# RL6845_IP_SVD register map
Vendor: Realtek
Registers are 32-bit, read-write, reset 0x0 unless marked. A register's access mark holds for its fields unless they carry their own. Offsets are from the block's base; [hi:lo] are bit positions; {n}, {i} and the like mark numbered series.

## LEDC_REG
Base 0x41105000
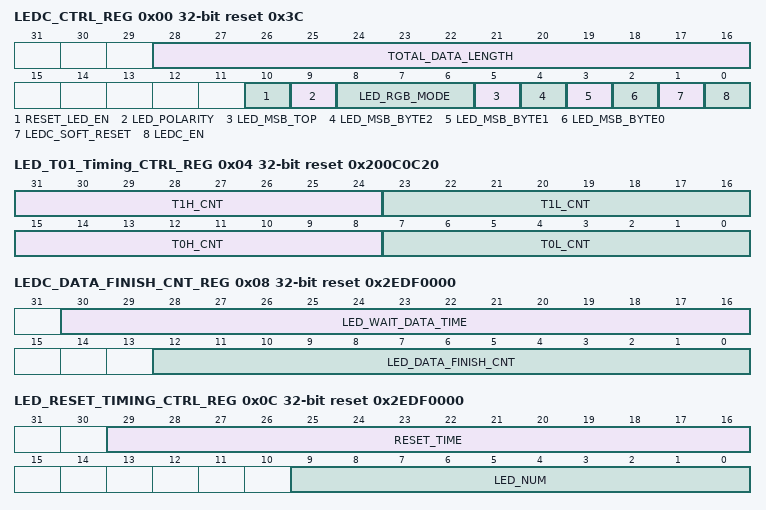
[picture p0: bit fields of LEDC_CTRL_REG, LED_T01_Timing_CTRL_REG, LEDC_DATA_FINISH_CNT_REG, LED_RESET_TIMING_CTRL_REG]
0x00 LEDC_CTRL_REG reset 0x3C — LEDC Control Register
  [28:16] TOTAL_DATA_LENGTH — Total length of transfer data, range from 1 to 8K (unit: 32 bits, only low 24-bit is valid). Actual transfer package is TOTAL_DATA_LENGTH+1. The field is recommended to an integer multiple of (LED_NUM+1). Note: If TOTAL_DATA_LENGTH is greater than (LED_NUM+1) but not integer multiple, the last frame of data will be transfered less than (LED_NUM+1).
  [10] RESET_LED_EN — Write operation: When software writes 1 to this bit, LEDC FSM turns to CPU_RESET_LED state, and CPU triggers LEDC to transfer a reset to LED. Note: Only when LEDC is in IDLE state, FSM can turn to CPU_RESET_LED state. * When LEDC finishs to send RESET to LED, LEDC FSM returns to the IDLE state, and hardware clears RESET_LED_EN. * Or when software sets SOFT_RESET, LEDC FSM returns to IDLE state, and hardware clears RESET_LED_EN. Read operation: 0: LEDC completes the transmission of LED reset operation. 1: LEDC does not complete the transmission of LED reset operation.
  [9] LED_POLARITY — LED DI level when free. 0: Low level 1: High level
  [8:6] LED_RGB_MODE — LEDC inputs 24 bits data package in order of {byte2, byte1, byte0}. 000: Output 24 bits data package in order of {byte2, byte1, byte0} 001: Output 24 bits data package in order of {byte2, byte0, byte1} 010: Output 24 bits data package in order of {byte1, byte2, byte0} 011: Output 24 bits data package in order of {byte0, byte2, byte1} 100: Output 24 bits data package in order of {byte1, byte0, byte2} 101: Output 24 bits data package in order of {byte0, byte1, byte2}
  [5] LED_MSB_TOP — Source RGB data format. 0: LSB 1: MSB
  [4] LED_MSB_BYTE2 — LEDC outputs 24 bits data package in order of {byte2, byte1, byte0}. 1: Output data byte2 MSB first 0: Output data byte2 LSB first
  [3] LED_MSB_BYTE1 — LEDC outputs 24 bits data package in order of {byte2, byte1, byte0}. 1: Output data byte1 MSB first 0: Output data byte1 LSB first
  [2] LED_MSB_BYTE0 — LEDC outputs 24 bits data package in order of {byte2, byte1, byte0}. 1: Output data byte0 MSB first 0: Output data byte0 LSB first
  [1] LEDC_SOFT_RESET — LEDC software reset. If software writes 1 to this bit, the next cycle hardware will clear LEDC_SOFT_RESET to 0, which will generate a pulse. LEDC soft reset includes all interrupt status register, the control state machine returns to the IDLE state, LEDC FIFO read and write point is cleared to 0, LEDC interrupt is cleared. The related registers are as below: * LEDC_CTRL_REG (LEDC_EN is cleared to 0) * LEDC_DATA_FINISH_CNT_REG (LEDC_DATA_FINISH_CNT is cleared to 0) * LEDC_INT_STS_REG (all interrupt are cleared) Other registers remain unchanged.
  [0] LEDC_EN — LEDC enable bit. 0: Disable 1: Enable This bit enable indicates that LEDC can be started when LEDC data has finished transmission, or this bit is cleared to 0 by hardware when software sets LEDC_SOFT_RESET. Software clearing LEDC_EN when LEDC FSM is not IDLE doesn't affect data transfer.
0x04 LED_T01_Timing_CTRL_REG reset 0x200C0C20 — LED Timing Control Register
  [31:24] T1H_CNT — LED modulate logical "1" high level time (T1H_TIME). Unit: cycle (40MHz), T1H_TIME = 25ns * T1H_CNT, where T1H_CNT>0 T1H_TIME default value is 800ns.
  [23:16] T1L_CNT — LED modulate logical "1" low level time. Unit: cycle (40MHz), T1L_TIME = 25ns *T1L_CNT, where T1L_CNT>0 T1L_TIME default value is 300ns.
  [15:8] T0H_CNT — LED modulate logical "0" high level time. Unit: cycle (40MHz), T0H_TIME = 25ns * T0H_CNT, where T0H_CNT>0 T0H_TIME default value is 300ns.
  [7:0] T0L_CNT — LED modulate logical "0" low level time. Unit: cycle (40MHz), T0L_TIME = 25ns *T0L_CNT, where T0L_CNT>0 T0L_TIME default value is 800ns.
0x08 LEDC_DATA_FINISH_CNT_REG access per field reset 0x2EDF0000 — LEDC Data Finish Register
  [30:16] LED_WAIT_DATA_TIME rw — The time that internal FIFO of LEDC is waiting for data. The default value is 300us by default. To avoid to insert LED RESET between two-pixel data, hardware will send WAITDATA_TIMEOUT_INT when wait_time>= min(RESET_TIME, LED_WAIT_DATA_TIME). The adjust range is from 25ns ~ 819us, LED_WAIT_DATA_TIME = 25ns *(N+1) where N is from 0 to 0x7FFF. When the setting time is exceeded, LEDC will send WAITDATA_TIMEOUT_INT interrupt. Under this abnormal situation, software should reset LEDC.
  [12:0] LED_DATA_FINISH_CNT ro — The total LED data have been sent (range: 0 ~ 8K). When LEDC transfer finishes normally, this register is cleared by hardware when generating trans_finish_int. Software knows LED_DATA_FINISH_CNT equal to TOTAL_DATA_LENGTH. When LEDC transfer interrupt abnormally, this register will be cleared to 0 by software by setting LEDC_SOFT_RESET.
0x0C LED_RESET_TIMING_CTRL_REG reset 0x2EDF0000 — LED Reset Timing Control Register
  [29:16] RESET_TIME — Reset time control of LED lamp. The default reset time is 300us. The adjust range is from 25ns to 409.6us. RESET_TIME = 25ns *(N+1) where N is from 0 to 0x3FFF.
  [9:0] LED_NUM — The number of external LED lamp. Maximum up to 1024. The default value is 0, which indicate that 1 LED lamp is connected. The range is from 0 to 1023.
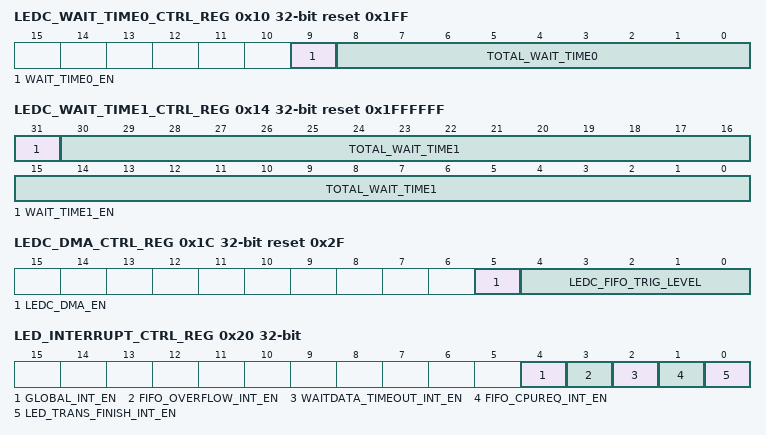
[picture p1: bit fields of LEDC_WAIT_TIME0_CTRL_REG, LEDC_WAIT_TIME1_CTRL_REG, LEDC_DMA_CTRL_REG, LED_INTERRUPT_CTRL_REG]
0x10 LEDC_WAIT_TIME0_CTRL_REG reset 0x1FF — LED Wait Time 0 Control Register
  [9] WAIT_TIME0_EN — Wait time0 enable. When setting this bit, the controller automatically inserts waiting time before next LED package data. 0: Disable 1: Enable
  [8:0] TOTAL_WAIT_TIME0 — Waiting time between 2 LED data, and LEDC outputs Low level during waiting time0. The adjust range is from 25ns to 12.5us, WAIT_TIME0 = 25ns*(N+1), where N is from 0 to 0x1FF.
0x14 LEDC_WAIT_TIME1_CTRL_REG reset 0x1FFFFFF — LED Wait Time 1 Control Register
  [31] WAIT_TIME1_EN — Wait time1 enable. When setting this bit, the controller automatically inserts waiting time before next LED frame data. 0: Disable 1: Enable
  [30:0] TOTAL_WAIT_TIME1 — Waiting time between 2 frame data, and LEDC outputs Low level during waiting time1. The adjust range is from 25ns to 53s, WAIT_TIME0 = 25ns*(N+1), where N is from 0 to 0x7FFFFFFF.
0x18 LEDC_DATA_REG wo — LED Data Register
  [23:0] LEDC_DATA — LEDC display data, the lower 24-bit is valid. Writ this register means push data to LEDC FIFO. Register LEDC_EN toggling from 0 to 1 will clear LEDC FIFO. Thus, only data pushed when LEDC_EN=1 will be send to LED.
0x1C LEDC_DMA_CTRL_REG reset 0x2F — LED DMA Control Register
  [5] LEDC_DMA_EN — LEDC DMA request enable. 0: Disable request of DMA transfer data 1: Enable request of DMA transfer data
  [4:0] LEDC_FIFO_TRIG_LEVEL — The remaining space of internal FIFO in LEDC. When the remain space of internal LEDC FIFO is larger than LEDC_FIFO_TRIG_LEVEL, a DMA request or cpu_req_int will generate. Note: The default value is 15. The adjust range is from 0 to 31, and the recommended configuration is 7 or 15.
0x20 LED_INTERRUPT_CTRL_REG — LED Interrupt Control Register
  [4] GLOBAL_INT_EN — Global interrupt enable. 0: Disable 1: Enable
  [3] FIFO_OVERFLOW_INT_EN — FIFO overflow interrupt enable. When the data written by software is more than internal FIFO level of LEDC, LEDC is in data loss state. 0: Disable 1: Enable
  [2] WAITDATA_TIMEOUT_INT_EN — The internal FIFO in LEDC can't get data after the LED_WAIT_DATA_TIME, the interrupt will be enable. 0: Disable 1: Enable
  [1] FIFO_CPUREQ_INT_EN — FIFO request CPU data interrupt enable. 0: Disable 1: Enable
  [0] LED_TRANS_FINISH_INT_EN — Data transmission complete interrupt enable. 0: Disable 1: Enable
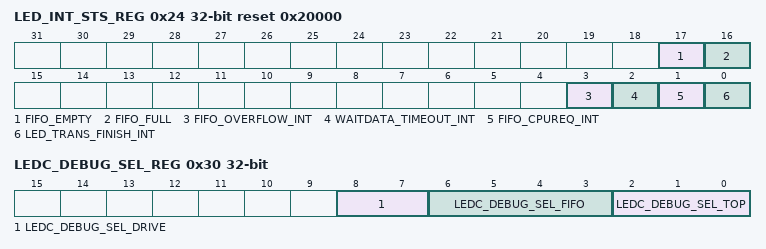
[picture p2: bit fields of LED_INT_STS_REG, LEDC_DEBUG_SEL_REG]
0x24 LED_INT_STS_REG ro reset 0x20000 — LED FIFO Status Register
  [17] FIFO_EMPTY — FIFO empty status flag. When LEDC_EN is 0, FIFO_EMPTY equal 1. This flush residual data when LED_NUM is not integer multiples of burst length.
  [16] FIFO_FULL — FIFO full status flag.
  [3] FIFO_OVERFLOW_INT — FIFO overflow interrupt Clear 0 when software set LEDC_SOFT_RESET. The data written by external is more than the maximum storage space of LEDC FIFO. At this time, software needs to deal with the abnormal situation. LEDC performs soft_reset operation to refresh all data. 0: FIFO does not overflow. 1: FIFO overflows.
  [2] WAITDATA_TIMEOUT_INT — Before transfer a frame: When the internal FIFO in LEDC can't get data after the LED_WAIT_DATA_TIME, this bit is set. During transfer of a frame (between two pixel of data): to avoid insert LED RESET between two pixel data, hardware will send WAITDATA_TIMEOUT_INT when wait_time>= min(RESET_TIME,LED_WAIT_DATA_TIME). Clear 0 when software sets LEDC_SOFT_RESET. When new data arrives at WAIT_DATA state, LEDC will continue sending data. Note: Software should note that if the waiting time exceeds the operation of reset time, LEDC may enter refresh state, new data has not been sent. 0: LEDC is not timeout. 1: LEDC is timeout.
  [1] FIFO_CPUREQ_INT — When FIFO data available is less than the threshold left, the interrupt is reported to CPU. Clear 0 when software sets LEDC_SOFT_RESET. 0: FIFO doesn't request CPU for data. 1: FIFO request CPU to transfer data. Note: When getting FIFO_CPUREQ_INT, CPU writes 1 data to LEDC Buffer. It is inefficiently compared to DMA mode.
  [0] LED_TRANS_FINISH_INT — When the data configured as TOTAL_DATA_LENGTH has been transferred complete, this bit is set. Clear 0 when software sets LEDC_SOFT_RESET. 0: Data transfer has not completed. 1: Data transfer has completed.
0x30 LEDC_DEBUG_SEL_REG — LED Debug Select Register
  [8:7] LEDC_DEBUG_SEL_DRIVE — Drive module debug out select.
  [6:3] LEDC_DEBUG_SEL_FIFO — FIFO module debug out select. [6:5]: select debug_data of ledc_txfifo, valid range is 0 or 1. [4:3]: select output data byte when bit[6:5] is 0. 2'b00: byte0 2'b01: byte1 2'b1x: byte2
  [2:0] LEDC_DEBUG_SEL_TOP — LEDC top module debug out select.
0xF0 DUMMY_F0 reset 0xFFFFFFFF — Dummy register
  [31:0] dummy
0xF4 DUMMY_F4 — Dummy register
  [31:0] dummy
